VERSION "1.0"

NS_ :

BS_:

BU_: PLC MotorDrive SensorNode Analyzer

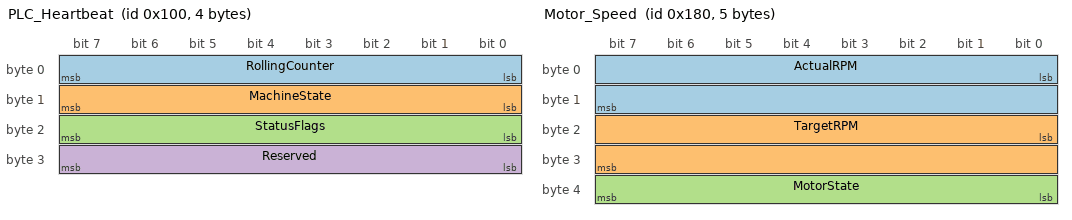
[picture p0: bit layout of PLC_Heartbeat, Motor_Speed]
BO_ 256 PLC_Heartbeat: 4 PLC
 SG_ RollingCounter : 0|8@1+ (1,0) [0|255] "" Analyzer
 SG_ MachineState : 8|8@1+ (1,0) [0|255] "" Analyzer
 SG_ StatusFlags : 16|8@1+ (1,0) [0|255] "" Analyzer
 SG_ Reserved : 24|8@1+ (1,0) [0|255] "" Analyzer

BO_ 384 Motor_Speed: 5 MotorDrive
 SG_ ActualRPM : 0|16@1+ (1,0) [0|65535] "rpm" Analyzer
 SG_ TargetRPM : 16|16@1+ (1,0) [0|65535] "rpm" Analyzer
 SG_ MotorState : 32|8@1+ (1,0) [0|255] "" Analyzer

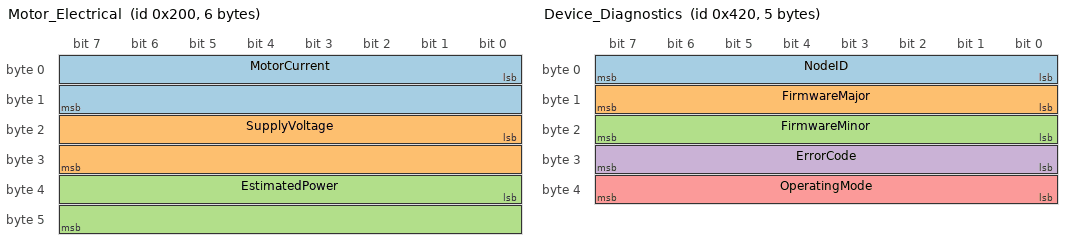
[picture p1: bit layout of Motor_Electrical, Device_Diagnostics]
BO_ 512 Motor_Electrical: 6 MotorDrive
 SG_ MotorCurrent : 0|16@1+ (0.01,0) [0|655.35] "A" Analyzer
 SG_ SupplyVoltage : 16|16@1+ (0.1,0) [0|6553.5] "V" Analyzer
 SG_ EstimatedPower : 32|16@1+ (10,0) [0|655350] "W" Analyzer

BO_ 640 Temperature_Data: 4 SensorNode
 SG_ MotorTemperature : 0|16@1+ (0.1,0) [0|6553.5] "degC" Analyzer
 SG_ AmbientTemperature : 16|16@1+ (0.1,0) [0|6553.5] "degC" Analyzer

BO_ 768 Digital_IO: 2 PLC
 SG_ InputFlags : 0|8@1+ (1,0) [0|255] "" Analyzer
 SG_ OutputFlags : 8|8@1+ (1,0) [0|255] "" Analyzer

BO_ 896 Production_Counter: 4 PLC
 SG_ ProductionCount : 0|32@1+ (1,0) [0|4294967295] "items" Analyzer

BO_ 1056 Device_Diagnostics: 5 PLC
 SG_ NodeID : 0|8@1+ (1,0) [0|255] "" Analyzer
 SG_ FirmwareMajor : 8|8@1+ (1,0) [0|255] "" Analyzer
 SG_ FirmwareMinor : 16|8@1+ (1,0) [0|255] "" Analyzer
 SG_ ErrorCode : 24|8@1+ (1,0) [0|255] "" Analyzer
 SG_ OperatingMode : 32|8@1+ (1,0) [0|255] "" Analyzer

CM_ BO_ 256 "PLC heartbeat and machine state. Expected period: 10 ms.";
CM_ SG_ 256 RollingCounter "Rolling 8-bit counter.";
CM_ SG_ 256 MachineState "1=Stopped/Idle, 2=Running.";
CM_ SG_ 256 StatusFlags "Bit 0=Running, Bit 1=Alarm.";

CM_ BO_ 384 "Motor speed feedback. Expected period: 20 ms.";
CM_ SG_ 384 ActualRPM "Actual motor shaft speed.";
CM_ SG_ 384 TargetRPM "Commanded motor speed.";
CM_ SG_ 384 MotorState "0=Stopped, 1=Running.";

CM_ BO_ 512 "Motor electrical measurements. Expected period: 50 ms.";
CM_ SG_ 512 MotorCurrent "Motor current scaled by 0.01 A/bit.";
CM_ SG_ 512 SupplyVoltage "Supply voltage scaled by 0.1 V/bit.";
CM_ SG_ 512 EstimatedPower "Estimated active power scaled by 10 W/bit.";

CM_ BO_ 640 "Motor and ambient temperatures. Expected period: 100 ms.";

CM_ BO_ 768 "Digital PLC I/O state. Expected period: 100 ms.";
CM_ SG_ 768 InputFlags "Bit 0=Start, Bit 1=MotorRunning, Bit 2=ProductSensor, Bit 3=SafetyDoorClosed, Bit 4=Alarm.";
CM_ SG_ 768 OutputFlags "Bit 0=MotorOutput.";

CM_ BO_ 896 "Production counter. Expected period: 500 ms.";

CM_ BO_ 1056 "Device diagnostics and firmware information. Expected period: 1000 ms.";

VAL_ 256 MachineState 1 "Idle" 2 "Running";
VAL_ 384 MotorState 0 "Stopped" 1 "Running";
VAL_ 1056 ErrorCode 0 "NoError" 1 "OverTemperature";
VAL_ 1056 OperatingMode 0 "Stopped" 1 "Running";

BA_DEF_ BO_ "GenMsgCycleTime" INT 0 65535;
BA_ "GenMsgCycleTime" BO_ 256 10;
BA_ "GenMsgCycleTime" BO_ 384 20;
BA_ "GenMsgCycleTime" BO_ 512 50;
BA_ "GenMsgCycleTime" BO_ 640 100;
BA_ "GenMsgCycleTime" BO_ 768 100;
BA_ "GenMsgCycleTime" BO_ 896 500;
BA_ "GenMsgCycleTime" BO_ 1056 1000;
